# R7FA6M2AF register map
Vendor: Renesas; Series: RA6; File version: 1.2
CPU: CM4 r0p1, little endian, MPU, FPU, VTOR, 4 interrupt priority bits
Registers are 8-bit, read-write, reset 0x0 unless marked. A register's access mark holds for its fields unless they carry their own. Offsets are from the block's base; [hi:lo] are bit positions; 'fields as' and 'values as' point back to an identical list.

## PORT0 — Port 0 Control Registers
Base 0x40040000
Same registers: PORT5 0x400400A0, PORT6 0x400400C0, PORT7 0x400400E0, PORT8 0x40040100, PORT9 0x40040120, PORTA 0x40040140, PORTB 0x40040160
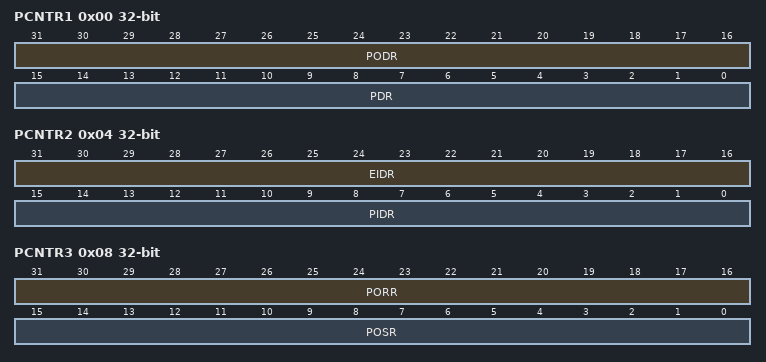
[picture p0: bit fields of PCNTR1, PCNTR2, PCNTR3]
0x00 PCNTR1 32-bit — Port Control Register 1
  [31:16] PODR — Pmn Output Data
    0=Low output; 1=High output
  [15:0] PDR — Pmn Direction
    0=Input (functions as an input pin); 1=Output (functions as an output pin)
0x00 PODR 16-bit (alternate view of PCNTR1) — Output data register
  [15:0] PODR — Pmn Output Data
    0=Low output; 1=High output
0x02 PDR 16-bit (alternate view of PCNTR1) — Data direction register
  [15:0] PDR — Pmn Direction
    values as PCNTR1.PDR
0x04 PCNTR2 32-bit ro (reset mask 0xFFFF0000) — Port Control Register 2
  [31:16] EIDR — Pmn Event Input Data
    0=Low input; 1=High input
  [15:0] PIDR — Pmn Input Data
    0=Low input; 1=High input
0x06 PIDR 16-bit ro reset not defined (alternate view of PCNTR2) — Input data register
  [15:0] PIDR — Pmn Input Data
    0=Low input; 1=High input
0x08 PCNTR3 32-bit wo — Port Control Register 3
  [31:16] PORR — Pmn Output Reset
    0=No affect to output; 1=Low output
  [15:0] POSR — Pmn Output Set
    0=No affect to output; 1=High output
0x08 PORR 16-bit wo (alternate view of PCNTR3) — Output reset register
  [15:0] PORR — Pmn Output Reset
    0=No affect to output; 1=Low output
0x0A POSR 16-bit wo (alternate view of PCNTR3) — Output set register
  [15:0] POSR — Pmn Output Set
    0=No affect to output; 1=High output

## PORT1 — Port 1 Control Registers
Base 0x40040020
Same registers: PORT2 0x40040040, PORT3 0x40040060, PORT4 0x40040080
Registers as PORT0; these are added or differ:
0x04 EIDR 16-bit ro reset not defined (alternate view of PCNTR2) — Event input data register
  [15:0] EIDR — Pmn Event Input Data
    0=Low input; 1=High input
0x08 PORR 16-bit wo (alternate view of PCNTR3) — Output set register
  [15:0] PORR — Pmn Output Reset
    0=No affect to output; 1=Low output
0x0A POSR 16-bit wo (alternate view of PCNTR3) — Output reset register
  [15:0] POSR — Pmn Output Set
    0=No affect to output; 1=High output
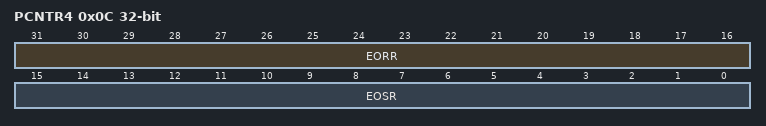
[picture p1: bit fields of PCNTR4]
0x0C PCNTR4 32-bit — Port Control Register 4
  [31:16] EORR — Pmn Event Output Reset
    0=No affect to output; 1=Low output
  [15:0] EOSR — Pmn Event Output Set
    0=No affect to output; 1=High output
0x0C EORR 16-bit (alternate view of PCNTR4) — Event output set register
  [15:0] EORR — Pmn Event Output Reset
    0=No affect to output; 1=Low output
0x0E EOSR 16-bit (alternate view of PCNTR4) — Event output reset register
  [15:0] EOSR — Pmn Event Output Set
    0=No affect to output; 1=High output

## PMISC — Miscellaneous Port Control Register
Base 0x40040D00
0x00 PFENET — Ethernet Control Register
  [4] PHYMODE0 — Ethernet Mode Setting ch0
    0=RMII mode (ETHERC channel 0); 1=MII mode (ETHERC channel 0)
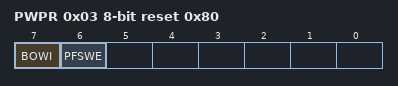
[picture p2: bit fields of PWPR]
0x03 PWPR reset 0x80 — Write-Protect Register
  [7] BOWI — PFSWE Bit Write Disable
    0=Writing to the PFSWE bit is enabled; 1=Writing to the PFSWE bit is disabled
  [6] PFSWE — PFS Register Write Enable
    0=Writing to the PFS register is disabled; 1=Writing to the PFS register is enabled

## GPT_OPS — Output Phase Switching Controller
Base 0x40078FF0
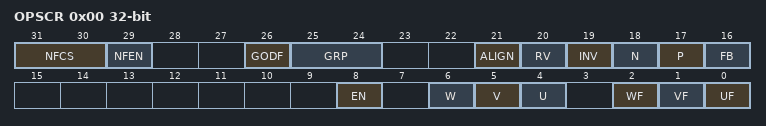
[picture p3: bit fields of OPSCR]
0x00 OPSCR 32-bit — Output Phase Switching Control Register
  [31:30] NFCS — External Input Noise Filter Clock selectionNoise filter sampling clock setting of the external input.
    0=PCLK/1; 1=PCLK/4; 2=PCLK/16; 3=PCLK/64
  [29] NFEN — External Input Noise Filter Enable
    0=Do not use a noise filter to the external input; 1=Use a noise filter to the external input
  [26] GODF — Group output disable function
    0=This bit function is ignored; 1=Group disable will clear OPSCR.EN Bit
  [25:24] GRP — Output disabled source selection
    0=Select Group A output disable source; 1=Select Group B output disable source; 2=Select Group C output disable source; 3=Select Group D output disable source
  [21] ALIGN — Input phase alignment
    0=Input phase is aligned to PCLK; 1=Input phase is aligned PWM
  [20] RV — Output phase rotation direction reversal
    0=U/V/W-Phase output; 1=Output to reverse the V / W-phase
  [19] INV — Invert-Phase Output Control
    0=Positive Logic (Active High)output; 1=Negative Logic (Active Low)output
  [18] N — Negative-Phase Output (N) Control
    0=Level signal output; 1=PWM signal output (PWM of GPT0)
  [17] P — Positive-Phase Output (P) Control
    0=Level signal output; 1=PWM signal output (PWM of GPT0)
  [16] FB — External Feedback Signal EnableThis bit selects the input phase from the software settings and external input.
    0=Select the external input; 1=Select the soft setting(OPSCR.UF, VF, WF)
  [8] EN — Enable-Phase Output Control
    0=Not Output(Hi-Z external terminals); 1=Output
  [6] W ro — Input W-Phase MonitorThis bit monitors the state of the input phase.OPSCR.FB=0:External input monitoring by PCLKOPSCR.FB=1:Software settings (UF/VF/WF)
  [5] V ro — Input V-Phase MonitorThis bit monitors the state of the input phase.OPSCR.FB=0:External input monitoring by PCLKOPSCR.FB=1:Software settings (UF/VF/WF)
  [4] U ro — Input U-Phase MonitorThis bit monitors the state of the input phase.OPSCR.FB=0:External input monitoring by PCLKOPSCR.FB=1:Software settings (UF/VF/WF)
  [2] WF — Input Phase Soft Setting UFThis bit sets the input phase by the software settings.This bit setting is valid when the OPSCR.FB bit = 1.
  [1] VF — Input Phase Soft Setting VFThis bit sets the input phase by the software settings.This bit setting is valid when the OPSCR.FB bit = 1.
  [0] UF — Input Phase Soft Setting WFThis bit sets the input phase by the software settings.This bit setting is valid when the OPSCR.FB bit = 1.
